AUTOSAR XML (schema 4-2-1)
package /RootP_ASWC_M410
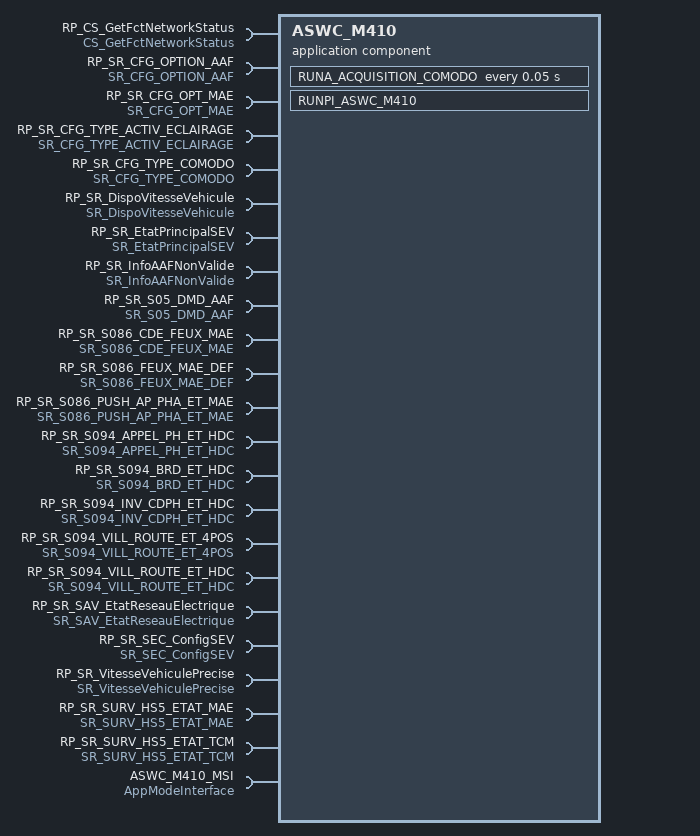
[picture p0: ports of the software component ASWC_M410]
  application sw component type ASWC_M410
    9 x provide/require port:
      PRP_SR_ArretSecu_SIGN_ECLE: nonqueued-receiver-com-spec{data-element=ArretSecu_SIGN_ECLE, enable-update=0, handle-data-status=1, handle-never-received=0, init-value=CONST_tLOG_1:1}, provided-required-interface=SR_ArretSecu_SIGN_ECLE
      PRP_SR_AUTOLightingAvailability: nonqueued-receiver-com-spec{data-element=AUTOLightingAvailability, enable-update=0, handle-data-status=1, handle-never-received=0, init-value=CONST_tLOG_0:0}, provided-required-interface=SR_AUTOLightingAvailability
      PRP_SR_AUTOLightingState: nonqueued-receiver-com-spec{data-element=AUTOLightingState, enable-update=0, handle-data-status=1, handle-never-received=0, init-value=CONST_tLOG_0:0}, provided-required-interface=SR_AUTOLightingState
      PRP_SR_DmdAntiBr_DEG: nonqueued-receiver-com-spec{data-element=DmdAntiBr_DEG, enable-update=0, handle-data-status=1, handle-never-received=0, init-value=CONST_tLOG_0:0}, provided-required-interface=SR_DmdAntiBr_DEG
      PRP_SR_DmdAntiBr_Moins: nonqueued-receiver-com-spec{data-element=DmdAntiBr_Moins, enable-update=0, handle-data-status=1, handle-never-received=0, init-value=CONST_tLOG_0:0}, provided-required-interface=SR_DmdAntiBr_Moins
      PRP_SR_DmdAntiBr_Plus: nonqueued-receiver-com-spec{data-element=DmdAntiBr_Plus, enable-update=0, handle-data-status=1, handle-never-received=0, init-value=CONST_tLOG_0:0}, provided-required-interface=SR_DmdAntiBr_Plus
      PRP_SR_DmdAppelPhare: nonqueued-receiver-com-spec{data-element=DmdAppelPhare, enable-update=0, handle-data-status=1, handle-never-received=0, init-value=CONST_tLOG_0:0}, provided-required-interface=SR_DmdAppelPhare
      PRP_SR_DmdInv_CROIS_ROUTE: nonqueued-receiver-com-spec{data-element=DmdInv_CROIS_ROUTE, enable-update=0, handle-data-status=1, handle-never-received=0, init-value=CONST_tLOG_0:0}, provided-required-interface=SR_DmdInv_CROIS_ROUTE
      PRP_SR_SynthDmdCommodo: nonqueued-receiver-com-spec{data-element=SynthDmdCommodo, enable-update=0, handle-data-status=1, handle-never-received=0, init-value=CONST_tBYTE_0:0}, provided-required-interface=SR_SynthDmdCommodo
    23 x require port:
      RP_CS_GetFctNetworkStatus: required-interface=CS_GetFctNetworkStatus
      RP_SR_CFG_OPTION_AAF: nonqueued-receiver-com-spec{data-element=CFG_OPTION_AAF, enable-update=0, handle-data-status=1, handle-never-received=0, init-value=CONST_tLOG_1:1}, required-interface=SR_CFG_OPTION_AAF
      RP_SR_CFG_OPT_MAE: nonqueued-receiver-com-spec{data-element=CFG_OPT_MAE, enable-update=0, handle-data-status=1, handle-never-received=0, init-value=CONST_tBYTE_0:0}, required-interface=SR_CFG_OPT_MAE
      RP_SR_CFG_TYPE_ACTIV_ECLAIRAGE: nonqueued-receiver-com-spec{data-element=CFG_TYPE_ACTIV_ECLAIRAGE, enable-update=0, handle-data-status=1, handle-never-received=0, init-value=CONST_t_cActiv_Par_0:0}, required-interface=SR_CFG_TYPE_ACTIV_ECLAIRAGE
      RP_SR_CFG_TYPE_COMODO: nonqueued-receiver-com-spec{data-element=CFG_TYPE_COMODO, enable-update=0, handle-data-status=1, handle-never-received=0, init-value=CONST_t_TYPE_COMODO_0:0}, required-interface=SR_CFG_TYPE_COMODO
      RP_SR_DispoVitesseVehicule: nonqueued-receiver-com-spec{data-element=DispoVitesseVehicule, enable-update=0, handle-data-status=1, handle-never-received=0, init-value=CONST_tBYTE_0x05:5}, required-interface=SR_DispoVitesseVehicule
      RP_SR_EtatPrincipalSEV: nonqueued-receiver-com-spec{data-element=EtatPrincipalSEV, enable-update=0, handle-data-status=1, handle-never-received=0, init-value=CONST_EtatPrincipalSEV_t_SEV_SEV_Arret:105}, required-interface=SR_EtatPrincipalSEV
      RP_SR_InfoAAFNonValide: nonqueued-receiver-com-spec{data-element=InfoAAFNonValide, enable-update=0, handle-data-status=1, handle-never-received=0, init-value=CONST_tLOG_0:0}, required-interface=SR_InfoAAFNonValide
      RP_SR_S05_DMD_AAF: nonqueued-receiver-com-spec{data-element=S05_DMD_AAF, enable-update=0, handle-data-status=1, handle-never-received=0, init-value=CONST_tLOG_0:0}, required-interface=SR_S05_DMD_AAF
      RP_SR_S086_CDE_FEUX_MAE: nonqueued-receiver-com-spec{data-element=S086_CDE_FEUX_MAE, enable-update=0, handle-data-status=1, handle-never-received=0, init-value=CONST_tQUARTET_1:1}, required-interface=SR_S086_CDE_FEUX_MAE
      RP_SR_S086_FEUX_MAE_DEF: nonqueued-receiver-com-spec{data-element=S086_FEUX_MAE_DEF, enable-update=0, handle-data-status=1, handle-never-received=0, init-value=CONST_tBILOG_0:0}, required-interface=SR_S086_FEUX_MAE_DEF
      RP_SR_S086_PUSH_AP_PHA_ET_MAE: nonqueued-receiver-com-spec{data-element=S086_PUSH_AP_PHA_ET_MAE, enable-update=0, handle-data-status=1, handle-never-received=0, init-value=CONST_tLOG_0:0}, required-interface=SR_S086_PUSH_AP_PHA_ET_MAE
      RP_SR_S094_APPEL_PH_ET_HDC: nonqueued-receiver-com-spec{data-element=S094_APPEL_PH_ET_HDC, enable-update=0, handle-data-status=1, handle-never-received=0, init-value=CONST_tLOG_0:0}, required-interface=SR_S094_APPEL_PH_ET_HDC
      RP_SR_S094_BRD_ET_HDC: nonqueued-receiver-com-spec{data-element=S094_BRD_ET_HDC, enable-update=0, handle-data-status=1, handle-never-received=0, init-value=CONST_tBILOG_0:0}, required-interface=SR_S094_BRD_ET_HDC
      RP_SR_S094_INV_CDPH_ET_HDC: nonqueued-receiver-com-spec{data-element=S094_INV_CDPH_ET_HDC, enable-update=0, handle-data-status=1, handle-never-received=0, init-value=CONST_tLOG_0:0}, required-interface=SR_S094_INV_CDPH_ET_HDC
      RP_SR_S094_VILL_ROUTE_ET_4POS: nonqueued-receiver-com-spec{data-element=S094_VILL_ROUTE_ET_4POS, enable-update=0, handle-data-status=1, handle-never-received=0, init-value=CONST_tQUARTET_1:1}, required-interface=SR_S094_VILL_ROUTE_ET_4POS
      RP_SR_S094_VILL_ROUTE_ET_HDC: nonqueued-receiver-com-spec{data-element=S094_VILL_ROUTE_ET_HDC, enable-update=0, handle-data-status=1, handle-never-received=0, init-value=CONST_tQUARTET_1:1}, required-interface=SR_S094_VILL_ROUTE_ET_HDC
      RP_SR_SAV_EtatReseauElectrique: nonqueued-receiver-com-spec{data-element=SAV_EtatReseauElectrique, enable-update=0, handle-data-status=1, handle-never-received=0, init-value=CONST_t_cGEE_1_0:0}, required-interface=SR_SAV_EtatReseauElectrique
      RP_SR_SEC_ConfigSEV: nonqueued-receiver-com-spec{data-element=SEC_ConfigSEV, enable-update=0, handle-data-status=1, handle-never-received=0, init-value=CONST_t_cCSEV_4:4}, required-interface=SR_SEC_ConfigSEV
      RP_SR_VitesseVehiculePrecise: nonqueued-receiver-com-spec{data-element=VitesseVehiculePrecise, enable-update=0, handle-data-status=1, handle-never-received=0, init-value=CONST_tWORD_0:0}, required-interface=SR_VitesseVehiculePrecise
      RP_SR_SURV_HS5_ETAT_MAE: nonqueued-receiver-com-spec{data-element=deSurvHs5EtatMae, alive-timeout=600, enable-update=0, handle-data-status=1, handle-never-received=0, init-value=CONST_tLOG_0:0}, required-interface=SR_SURV_HS5_ETAT_MAE
      RP_SR_SURV_HS5_ETAT_TCM: nonqueued-receiver-com-spec{data-element=deSurvHs5EtatTcm, alive-timeout=300, enable-update=0, handle-data-status=1, handle-never-received=0, init-value=CONST_tLOG_0:0}, required-interface=SR_SURV_HS5_ETAT_TCM
      ASWC_M410_MSI: required-interface=AppModeInterface
    behavior IB_ASWC_M410: data-type-mapping=ApplicationModeMapping, handle-termination-and-restart=NO-SUPPORT
      timing event RUNA_ACQUISITION_COMODO_Cyclic: start-on-event=RUNA_ACQUISITION_COMODO, period=0.05
        disabled-mode:
          ASWC_M410_MSI.AppMode.APP_WAKEUP
          ASWC_M410_MSI.AppMode.APP_OFF
          ASWC_M410_MSI.AppMode.APP_SYNC_INIT
          ASWC_M410_MSI.AppMode.APP_CONFIG
      swc mode switch event RUNPI_ASWC_M410_ENTRY: start-on-event=RUNPI_ASWC_M410, activation=ON-ENTRY, mode=ASWC_M410_MSI.AppMode.APP_WAKEUP
      runnable RUNA_ACQUISITION_COMODO
        data-read-access:
          30 x access:
            dra_RP_SR_DispoVitesseVehicule_DispoVitesseVehicule: accessed-variable=RP_SR_DispoVitesseVehicule.DispoVitesseVehicule
            dra_RP_SR_EtatPrincipalSEV_EtatPrincipalSEV: accessed-variable=RP_SR_EtatPrincipalSEV.EtatPrincipalSEV
            dra_RP_SR_InfoAAFNonValide_InfoAAFNonValide: accessed-variable=RP_SR_InfoAAFNonValide.InfoAAFNonValide
            dra_RP_SR_S05_DMD_AAF_S05_DMD_AAF: accessed-variable=RP_SR_S05_DMD_AAF.S05_DMD_AAF
            dra_RP_SR_S086_CDE_FEUX_MAE_S086_CDE_FEUX_MAE: accessed-variable=RP_SR_S086_CDE_FEUX_MAE.S086_CDE_FEUX_MAE
            dra_RP_SR_S086_FEUX_MAE_DEF_S086_FEUX_MAE_DEF: accessed-variable=RP_SR_S086_FEUX_MAE_DEF.S086_FEUX_MAE_DEF
            dra_RP_SR_S086_PUSH_AP_PHA_ET_MAE_S086_PUSH_AP_PHA_ET_MAE: accessed-variable=RP_SR_S086_PUSH_AP_PHA_ET_MAE.S086_PUSH_AP_PHA_ET_MAE
            dra_RP_SR_S094_APPEL_PH_ET_HDC_S094_APPEL_PH_ET_HDC: accessed-variable=RP_SR_S094_APPEL_PH_ET_HDC.S094_APPEL_PH_ET_HDC
            dra_RP_SR_S094_BRD_ET_HDC_S094_BRD_ET_HDC: accessed-variable=RP_SR_S094_BRD_ET_HDC.S094_BRD_ET_HDC
            dra_RP_SR_S094_INV_CDPH_ET_HDC_S094_INV_CDPH_ET_HDC: accessed-variable=RP_SR_S094_INV_CDPH_ET_HDC.S094_INV_CDPH_ET_HDC
            dra_RP_SR_S094_VILL_ROUTE_ET_4POS_S094_VILL_ROUTE_ET_4POS: accessed-variable=RP_SR_S094_VILL_ROUTE_ET_4POS.S094_VILL_ROUTE_ET_4POS
            dra_RP_SR_S094_VILL_ROUTE_ET_HDC_S094_VILL_ROUTE_ET_HDC: accessed-variable=RP_SR_S094_VILL_ROUTE_ET_HDC.S094_VILL_ROUTE_ET_HDC
            dra_RP_SR_SAV_EtatReseauElectrique_SAV_EtatReseauElectrique: accessed-variable=RP_SR_SAV_EtatReseauElectrique.SAV_EtatReseauElectrique
            dra_RP_SR_SEC_ConfigSEV_SEC_ConfigSEV: accessed-variable=RP_SR_SEC_ConfigSEV.SEC_ConfigSEV
            dra_RP_SR_VitesseVehiculePrecise_VitesseVehiculePrecise: accessed-variable=RP_SR_VitesseVehiculePrecise.VitesseVehiculePrecise
            dra_RP_SR_SURV_HS5_ETAT_MAE_deSurvHs5EtatMae: accessed-variable=RP_SR_SURV_HS5_ETAT_MAE.deSurvHs5EtatMae
            dra_RP_SR_SURV_HS5_ETAT_TCM_deSurvHs5EtatTcm: accessed-variable=RP_SR_SURV_HS5_ETAT_TCM.deSurvHs5EtatTcm
            dra_RP_SR_CFG_OPTION_AAF_CFG_OPTION_AAF: accessed-variable=RP_SR_CFG_OPTION_AAF.CFG_OPTION_AAF
            dra_RP_SR_CFG_OPT_MAE_CFG_OPT_MAE: accessed-variable=RP_SR_CFG_OPT_MAE.CFG_OPT_MAE
            dra_RP_SR_CFG_TYPE_ACTIV_ECLAIRAGE_CFG_TYPE_ACTIV_ECLAIRAGE: accessed-variable=RP_SR_CFG_TYPE_ACTIV_ECLAIRAGE.CFG_TYPE_ACTIV_ECLAIRAGE
            dra_RP_SR_CFG_TYPE_COMODO_CFG_TYPE_COMODO: accessed-variable=RP_SR_CFG_TYPE_COMODO.CFG_TYPE_COMODO
            dra_PRP_SR_ArretSecu_SIGN_ECLE_ArretSecu_SIGN_ECLE: accessed-variable=PRP_SR_ArretSecu_SIGN_ECLE.ArretSecu_SIGN_ECLE
            dra_PRP_SR_AUTOLightingAvailability_AUTOLightingAvailability: accessed-variable=PRP_SR_AUTOLightingAvailability.AUTOLightingAvailability
            dra_PRP_SR_AUTOLightingState_AUTOLightingState: accessed-variable=PRP_SR_AUTOLightingState.AUTOLightingState
            dra_PRP_SR_DmdAntiBr_DEG_DmdAntiBr_DEG: accessed-variable=PRP_SR_DmdAntiBr_DEG.DmdAntiBr_DEG
            dra_PRP_SR_DmdAntiBr_Moins_DmdAntiBr_Moins: accessed-variable=PRP_SR_DmdAntiBr_Moins.DmdAntiBr_Moins
            dra_PRP_SR_DmdAntiBr_Plus_DmdAntiBr_Plus: accessed-variable=PRP_SR_DmdAntiBr_Plus.DmdAntiBr_Plus
            dra_PRP_SR_DmdAppelPhare_DmdAppelPhare: accessed-variable=PRP_SR_DmdAppelPhare.DmdAppelPhare
            dra_PRP_SR_DmdInv_CROIS_ROUTE_DmdInv_CROIS_ROUTE: accessed-variable=PRP_SR_DmdInv_CROIS_ROUTE.DmdInv_CROIS_ROUTE
            dra_PRP_SR_SynthDmdCommodo_SynthDmdCommodo: accessed-variable=PRP_SR_SynthDmdCommodo.SynthDmdCommodo
        data-write-access:
          9 x access:
            dwa_PRP_SR_ArretSecu_SIGN_ECLE_ArretSecu_SIGN_ECLE: accessed-variable=PRP_SR_ArretSecu_SIGN_ECLE.ArretSecu_SIGN_ECLE
            dwa_PRP_SR_AUTOLightingAvailability_AUTOLightingAvailability: accessed-variable=PRP_SR_AUTOLightingAvailability.AUTOLightingAvailability
            dwa_PRP_SR_AUTOLightingState_AUTOLightingState: accessed-variable=PRP_SR_AUTOLightingState.AUTOLightingState
            dwa_PRP_SR_DmdAntiBr_DEG_DmdAntiBr_DEG: accessed-variable=PRP_SR_DmdAntiBr_DEG.DmdAntiBr_DEG
            dwa_PRP_SR_DmdAntiBr_Moins_DmdAntiBr_Moins: accessed-variable=PRP_SR_DmdAntiBr_Moins.DmdAntiBr_Moins
            dwa_PRP_SR_DmdAntiBr_Plus_DmdAntiBr_Plus: accessed-variable=PRP_SR_DmdAntiBr_Plus.DmdAntiBr_Plus
            dwa_PRP_SR_DmdAppelPhare_DmdAppelPhare: accessed-variable=PRP_SR_DmdAppelPhare.DmdAppelPhare
            dwa_PRP_SR_DmdInv_CROIS_ROUTE_DmdInv_CROIS_ROUTE: accessed-variable=PRP_SR_DmdInv_CROIS_ROUTE.DmdInv_CROIS_ROUTE
            dwa_PRP_SR_SynthDmdCommodo_SynthDmdCommodo: accessed-variable=PRP_SR_SynthDmdCommodo.SynthDmdCommodo
        sync call sscp_RUNA_ACQUISITION_COMODO_CS_GetFctNetworkStatus_Get: operation=RP_CS_GetFctNetworkStatus.Get, timeout=0
      runnable RUNPI_ASWC_M410
package /RootP_Implementatation
  swc implementation Implementatation_ASWC_M410: programming-language=C, sw-version=1.0.0, vendor-id=1, behavior=IB_ASWC_M410
    code-descriptors:
      code SRC: artifact-descriptors=autosar-engineering-object={short-label=EngObject, category=SWSRC}
    resource consumption Resources
